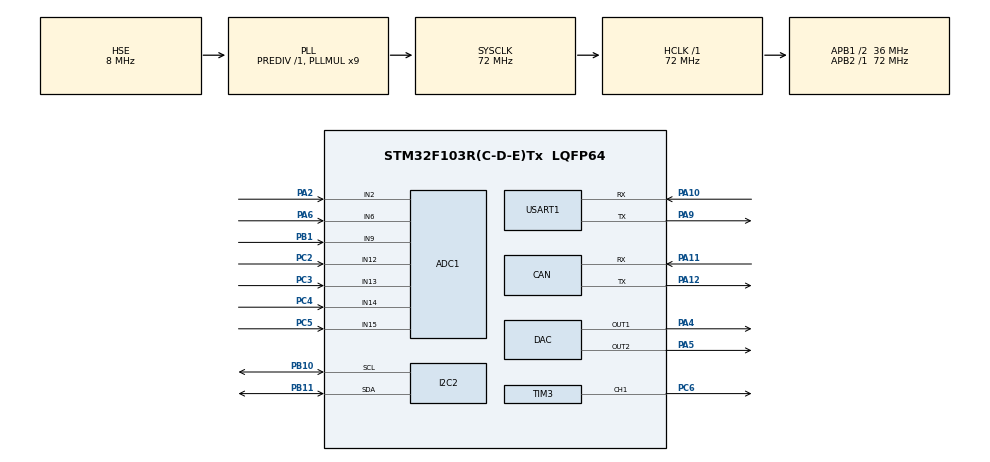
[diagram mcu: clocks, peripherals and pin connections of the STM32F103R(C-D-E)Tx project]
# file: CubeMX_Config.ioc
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ADC1.Channel-0\#ChannelRegularConversion=ADC_CHANNEL_12
ADC1.Channel-1\#ChannelRegularConversion=ADC_CHANNEL_13
ADC1.Channel-2\#ChannelRegularConversion=ADC_CHANNEL_2
ADC1.Channel-3\#ChannelRegularConversion=ADC_CHANNEL_14
ADC1.Channel-4\#ChannelRegularConversion=ADC_CHANNEL_6
ADC1.Channel-5\#ChannelRegularConversion=ADC_CHANNEL_9
ADC1.Channel-6\#ChannelRegularConversion=ADC_CHANNEL_15
ADC1.Channel-7\#ChannelRegularConversion=ADC_CHANNEL_VREFINT
ADC1.ContinuousConvMode=DISABLE
ADC1.ExternalTrigConv=ADC_EXTERNALTRIGCONV_T8_TRGO
ADC1.NbrOfConversion=8
ADC1.NbrOfConversionFlag=1
ADC1.Rank-0\#ChannelRegularConversion=1
ADC1.Rank-1\#ChannelRegularConversion=2
ADC1.Rank-2\#ChannelRegularConversion=3
ADC1.Rank-3\#ChannelRegularConversion=4
ADC1.Rank-4\#ChannelRegularConversion=5
ADC1.Rank-5\#ChannelRegularConversion=6
ADC1.Rank-6\#ChannelRegularConversion=7
ADC1.Rank-7\#ChannelRegularConversion=8
ADC1.SamplingTime-0\#ChannelRegularConversion=ADC_SAMPLETIME_1CYCLE_5
ADC1.SamplingTime-1\#ChannelRegularConversion=ADC_SAMPLETIME_1CYCLE_5
ADC1.SamplingTime-2\#ChannelRegularConversion=ADC_SAMPLETIME_1CYCLE_5
ADC1.SamplingTime-3\#ChannelRegularConversion=ADC_SAMPLETIME_1CYCLE_5
ADC1.SamplingTime-4\#ChannelRegularConversion=ADC_SAMPLETIME_1CYCLE_5
ADC1.SamplingTime-5\#ChannelRegularConversion=ADC_SAMPLETIME_1CYCLE_5
ADC1.SamplingTime-6\#ChannelRegularConversion=ADC_SAMPLETIME_1CYCLE_5
ADC1.SamplingTime-7\#ChannelRegularConversion=ADC_SAMPLETIME_1CYCLE_5
ADC1.master=1
CAN.CalculateTimeBit=1333.33
CAN.CalculateTimeQuantum=444.44444444444446
Dma.ADC1.0.Direction=DMA_PERIPH_TO_MEMORY
Dma.ADC1.0.Instance=DMA1_Channel1
Dma.ADC1.0.MemDataAlignment=DMA_MDATAALIGN_HALFWORD
Dma.ADC1.0.MemInc=DMA_MINC_ENABLE
Dma.ADC1.0.Mode=DMA_CIRCULAR
Dma.ADC1.0.PeriphDataAlignment=DMA_PDATAALIGN_HALFWORD
Dma.ADC1.0.PeriphInc=DMA_PINC_DISABLE
Dma.ADC1.0.Priority=DMA_PRIORITY_HIGH
Dma.Request0=ADC1
I2C2.DutyCycle=I2C_DUTYCYCLE_16_9
I2C2.I2C_Mode=I2C_Fast
Mcu.Family=STM32F1
Mcu.Name=STM32F103R(C-D-E)Tx
Mcu.Package=LQFP64
NVIC.DMA1_Channel1_IRQn=true\:0\:0\:false\:false\:true\:false\:true
NVIC.PriorityGroup=NVIC_PRIORITYGROUP_4
PA10.Mode=Asynchronous
PA10.Signal=USART1_RX
PA11.Mode=Master
PA11.Signal=CAN_RX
PA12.Mode=Master
PA12.Signal=CAN_TX
PA13.Mode=Serial_Wire
PA13.Signal=SYS_JTMS-SWDIO
PA14.Mode=Serial_Wire
PA14.Signal=SYS_JTCK-SWCLK
PA2.Signal=ADCx_IN2
PA4.Signal=COMP_DAC1_group
PA5.Signal=COMP_DAC2_group
PA6.Signal=ADCx_IN6
PA9.Mode=Asynchronous
PA9.Signal=USART1_TX
PB1.Signal=ADCx_IN9
PB10.Mode=I2C
PB10.Signal=I2C2_SCL
PB11.Mode=I2C
PB11.Signal=I2C2_SDA
PC2.Signal=ADCx_IN12
PC3.Signal=ADCx_IN13
PC4.Signal=ADCx_IN14
PC5.Signal=ADCx_IN15
PC6.Signal=S_TIM3_CH1
PD0-OSC_IN.Mode=HSE-External-Oscillator
PD0-OSC_IN.Signal=RCC_OSC_IN
PD1-OSC_OUT.Mode=HSE-External-Oscillator
PD1-OSC_OUT.Signal=RCC_OSC_OUT
ProjectManager.HeapSize=0x200
ProjectManager.StackSize=0x400
ProjectManager.TargetToolchain=MDK-ARM V5
RCC.ADCPresc=RCC_ADCPCLK2_DIV6
RCC.AHBFreq_Value=72000000
RCC.APB1CLKDivider=RCC_HCLK_DIV2
RCC.APB1Freq_Value=36000000
RCC.APB1TimFreq_Value=72000000
RCC.APB2Freq_Value=72000000
RCC.APB2TimFreq_Value=72000000
RCC.HCLKFreq_Value=72000000
RCC.PLLMUL=RCC_PLL_MUL9
RCC.PLLSourceVirtual=RCC_PLLSOURCE_HSE
RCC.SYSCLKFreq_VALUE=72000000
RCC.SYSCLKSource=RCC_SYSCLKSOURCE_PLLCLK
RCC.USBFreq_Value=72000000
SH.ADCx_IN12.0=ADC1_IN12,IN12
SH.ADCx_IN13.0=ADC1_IN13,IN13
SH.ADCx_IN14.0=ADC1_IN14,IN14
SH.ADCx_IN15.0=ADC1_IN15,IN15
SH.ADCx_IN2.0=ADC1_IN2,IN2
SH.ADCx_IN6.0=ADC1_IN6,IN6
SH.ADCx_IN9.0=ADC1_IN9,IN9
SH.COMP_DAC1_group.0=DAC_OUT1,DAC_OUT1
SH.COMP_DAC2_group.0=DAC_OUT2,DAC_OUT2
SH.S_TIM3_CH1.0=TIM3_CH1,PWM Generation1 CH1
TIM3.Channel-PWM\ Generation1\ CH1=TIM_CHANNEL_1
TIM8.AutoReloadPreload=TIM_AUTORELOAD_PRELOAD_ENABLE
TIM8.Period=199
TIM8.Prescaler=71
TIM8.TIM_MasterOutputTrigger=TIM_TRGO_UPDATE
TIM8.TIM_MasterSlaveMode=TIM_MASTERSLAVEMODE_ENABLE
USART1.VirtualMode=VM_ASYNC
VP_ADC1_Vref_Input.Mode=IN-Vrefint
VP_IWDG_VS_IWDG.Mode=IWDG_Activate
VP_TIM2_VS_ClockSourceINT.Mode=Internal
VP_TIM3_VS_ClockSourceINT.Mode=Internal
VP_TIM8_VS_ClockSourceINT.Mode=Internal
board=custom

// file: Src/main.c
/* USER CODE BEGIN Header */
/**
  ******************************************************************************
  * @file           : main.c
  * @brief          : Main program body
  ******************************************************************************
  * @attention
  *
  * <h2><center>&copy; Copyright (c) 2020 STMicroelectronics.
  * All rights reserved.</center></h2>
  *
  * This software component is licensed by ST under BSD 3-Clause license,
  * the "License"; You may not use this file except in compliance with the
  * License. You may obtain a copy of the License at:
  *                        opensource.org/licenses/BSD-3-Clause
  *
  ******************************************************************************
  */
/* USER CODE END Header */

#include "main.h"

ADC_HandleTypeDef hadc1;
DMA_HandleTypeDef hdma_adc1;

CAN_HandleTypeDef hcan;

DAC_HandleTypeDef hdac;

I2C_HandleTypeDef hi2c2;

IWDG_HandleTypeDef hiwdg;

TIM_HandleTypeDef htim2;
TIM_HandleTypeDef htim3;
TIM_HandleTypeDef htim8;

UART_HandleTypeDef huart1;

/* USER CODE BEGIN PV */
uint16_t adc_data_Buff[1][8]; // 用于存放adc采样数据的数组
/* USER CODE END PV */

void SystemClock_Config(void);
static void MX_GPIO_Init(void);
static void MX_ADC1_Init(void);
static void MX_CAN_Init(void);
static void MX_DAC_Init(void);
static void MX_TIM3_Init(void);
static void MX_USART1_UART_Init(void);
static void MX_I2C2_Init(void);
static void MX_DMA_Init(void);
static void MX_IWDG_Init(void);
static void MX_TIM8_Init(void);
static void MX_TIM2_Init(void);

int main(void)
{

  /* MCU Configuration--------------------------------------------------------*/

  /* Reset of all peripherals, Initializes the Flash interface and the Systick. */
  HAL_Init();

  /* Configure the system clock */
  SystemClock_Config();

  /* Initialize all configured peripherals */
  MX_GPIO_Init();
	MX_DMA_Init();
  MX_ADC1_Init();
  MX_CAN_Init();
  MX_DAC_Init();
  MX_TIM3_Init();
  MX_USART1_UART_Init();
  MX_I2C2_Init();
  MX_IWDG_Init();
  MX_TIM8_Init();
  MX_TIM2_Init();
  /* USER CODE BEGIN 2 */
	HAL_ADC_Start_DMA(&hadc1, (uint32_t *)adc_data_Buff, 8); //启动DMA
	HAL_TIM_Base_Start_IT(&htim8);												//启动定时器，触发ADC-DMA采样
	HAL_Delay(100);
  /* USER CODE END 2 */

  /* Infinite loop */
  while (1)
  {

  }
}

void SystemClock_Config(void)
{
  RCC_OscInitTypeDef RCC_OscInitStruct = {0};
  RCC_ClkInitTypeDef RCC_ClkInitStruct = {0};
  RCC_PeriphCLKInitTypeDef PeriphClkInit = {0};

  /** Initializes the CPU, AHB and APB busses clocks
  */
  RCC_OscInitStruct.OscillatorType = RCC_OSCILLATORTYPE_LSI|RCC_OSCILLATORTYPE_HSE;
  RCC_OscInitStruct.HSEState = RCC_HSE_ON;
  RCC_OscInitStruct.HSEPredivValue = RCC_HSE_PREDIV_DIV1;
  RCC_OscInitStruct.HSIState = RCC_HSI_ON;
  RCC_OscInitStruct.LSIState = RCC_LSI_ON;
  RCC_OscInitStruct.PLL.PLLState = RCC_PLL_ON;
  RCC_OscInitStruct.PLL.PLLSource = RCC_PLLSOURCE_HSE;
  RCC_OscInitStruct.PLL.PLLMUL = RCC_PLL_MUL9;
  if (HAL_RCC_OscConfig(&RCC_OscInitStruct) != HAL_OK)
  {
    Error_Handler();
  }
  /** Initializes the CPU, AHB and APB busses clocks
  */
  RCC_ClkInitStruct.ClockType = RCC_CLOCKTYPE_HCLK|RCC_CLOCKTYPE_SYSCLK
                              |RCC_CLOCKTYPE_PCLK1|RCC_CLOCKTYPE_PCLK2;
  RCC_ClkInitStruct.SYSCLKSource = RCC_SYSCLKSOURCE_PLLCLK;
  RCC_ClkInitStruct.AHBCLKDivider = RCC_SYSCLK_DIV1;
  RCC_ClkInitStruct.APB1CLKDivider = RCC_HCLK_DIV2;
  RCC_ClkInitStruct.APB2CLKDivider = RCC_HCLK_DIV1;

  if (HAL_RCC_ClockConfig(&RCC_ClkInitStruct, FLASH_LATENCY_2) != HAL_OK)
  {
    Error_Handler();
  }
  PeriphClkInit.PeriphClockSelection = RCC_PERIPHCLK_ADC;
  PeriphClkInit.AdcClockSelection = RCC_ADCPCLK2_DIV6;
  if (HAL_RCCEx_PeriphCLKConfig(&PeriphClkInit) != HAL_OK)
  {
    Error_Handler();
  }
}

static void MX_ADC1_Init(void)
{

  ADC_ChannelConfTypeDef sConfig = {0};

  /** Common config
  */
  hadc1.Instance = ADC1;
  hadc1.Init.ScanConvMode = ADC_SCAN_ENABLE;
  hadc1.Init.ContinuousConvMode = DISABLE;
  hadc1.Init.DiscontinuousConvMode = DISABLE;
  hadc1.Init.ExternalTrigConv = ADC_EXTERNALTRIGCONV_T8_TRGO;
  hadc1.Init.DataAlign = ADC_DATAALIGN_RIGHT;
  hadc1.Init.NbrOfConversion = 8;
  if (HAL_ADC_Init(&hadc1) != HAL_OK)
  {
    Error_Handler();
  }
  /** Enable or disable the remapping of ADC1_ETRGREG:
  * ADC1 External Event regular conversion is connected to TIM8 TRG0
  */
  __HAL_AFIO_REMAP_ADC1_ETRGREG_ENABLE();
  /** Configure Regular Channel
  */
  sConfig.Channel = ADC_CHANNEL_12;
  sConfig.Rank = ADC_REGULAR_RANK_1;
  sConfig.SamplingTime = ADC_SAMPLETIME_1CYCLE_5;
  if (HAL_ADC_ConfigChannel(&hadc1, &sConfig) != HAL_OK)
  {
    Error_Handler();
  }
  /** Configure Regular Channel
  */
  sConfig.Channel = ADC_CHANNEL_13;
  sConfig.Rank = ADC_REGULAR_RANK_2;
  if (HAL_ADC_ConfigChannel(&hadc1, &sConfig) != HAL_OK)
  {
    Error_Handler();
  }
  /** Configure Regular Channel
  */
  sConfig.Channel = ADC_CHANNEL_2;
  sConfig.Rank = ADC_REGULAR_RANK_3;
  if (HAL_ADC_ConfigChannel(&hadc1, &sConfig) != HAL_OK)
  {
    Error_Handler();
  }
  /** Configure Regular Channel
  */
  sConfig.Channel = ADC_CHANNEL_14;
  sConfig.Rank = ADC_REGULAR_RANK_4;
  if (HAL_ADC_ConfigChannel(&hadc1, &sConfig) != HAL_OK)
  {
    Error_Handler();
  }
  /** Configure Regular Channel
  */
  sConfig.Channel = ADC_CHANNEL_6;
  sConfig.Rank = ADC_REGULAR_RANK_5;
  if (HAL_ADC_ConfigChannel(&hadc1, &sConfig) != HAL_OK)
  {
    Error_Handler();
  }
  /** Configure Regular Channel
  */
  sConfig.Channel = ADC_CHANNEL_9;
  sConfig.Rank = ADC_REGULAR_RANK_6;
  if (HAL_ADC_ConfigChannel(&hadc1, &sConfig) != HAL_OK)
  {
    Error_Handler();
  }
  /** Configure Regular Channel
  */
  sConfig.Channel = ADC_CHANNEL_15;
  sConfig.Rank = ADC_REGULAR_RANK_7;
  if (HAL_ADC_ConfigChannel(&hadc1, &sConfig) != HAL_OK)
  {
    Error_Handler();
  }
  /** Configure Regular Channel
  */
  sConfig.Channel = ADC_CHANNEL_VREFINT;
  sConfig.Rank = ADC_REGULAR_RANK_8;
  if (HAL_ADC_ConfigChannel(&hadc1, &sConfig) != HAL_OK)
  {
    Error_Handler();
  }

}

static void MX_CAN_Init(void)
{

  hcan.Instance = CAN1;
  hcan.Init.Prescaler = 16;
  hcan.Init.Mode = CAN_MODE_NORMAL;
  hcan.Init.SyncJumpWidth = CAN_SJW_1TQ;
  hcan.Init.TimeSeg1 = CAN_BS1_1TQ;
  hcan.Init.TimeSeg2 = CAN_BS2_1TQ;
  hcan.Init.TimeTriggeredMode = DISABLE;
  hcan.Init.AutoBusOff = DISABLE;
  hcan.Init.AutoWakeUp = DISABLE;
  hcan.Init.AutoRetransmission = DISABLE;
  hcan.Init.ReceiveFifoLocked = DISABLE;
  hcan.Init.TransmitFifoPriority = DISABLE;
  if (HAL_CAN_Init(&hcan) != HAL_OK)
  {
    Error_Handler();
  }

}

static void MX_DAC_Init(void)
{

  DAC_ChannelConfTypeDef sConfig = {0};

  /** DAC Initialization
  */
  hdac.Instance = DAC;
  if (HAL_DAC_Init(&hdac) != HAL_OK)
  {
    Error_Handler();
  }
  /** DAC channel OUT1 config
  */
  sConfig.DAC_Trigger = DAC_TRIGGER_NONE;
  sConfig.DAC_OutputBuffer = DAC_OUTPUTBUFFER_ENABLE;
  if (HAL_DAC_ConfigChannel(&hdac, &sConfig, DAC_CHANNEL_1) != HAL_OK)
  {
    Error_Handler();
  }
  /** DAC channel OUT2 config
  */
  if (HAL_DAC_ConfigChannel(&hdac, &sConfig, DAC_CHANNEL_2) != HAL_OK)
  {
    Error_Handler();
  }

}

static void MX_I2C2_Init(void)
{

  hi2c2.Instance = I2C2;
  hi2c2.Init.ClockSpeed = 400000;
  hi2c2.Init.DutyCycle = I2C_DUTYCYCLE_16_9;
  hi2c2.Init.OwnAddress1 = 0;
  hi2c2.Init.AddressingMode = I2C_ADDRESSINGMODE_7BIT;
  hi2c2.Init.DualAddressMode = I2C_DUALADDRESS_DISABLE;
  hi2c2.Init.OwnAddress2 = 0;
  hi2c2.Init.GeneralCallMode = I2C_GENERALCALL_DISABLE;
  hi2c2.Init.NoStretchMode = I2C_NOSTRETCH_DISABLE;
  if (HAL_I2C_Init(&hi2c2) != HAL_OK)
  {
    Error_Handler();
  }

}

static void MX_IWDG_Init(void)
{

  hiwdg.Instance = IWDG;
  hiwdg.Init.Prescaler = IWDG_PRESCALER_4;
  hiwdg.Init.Reload = 4095;
  if (HAL_IWDG_Init(&hiwdg) != HAL_OK)
  {
    Error_Handler();
  }

}

static void MX_TIM2_Init(void)
{

  TIM_ClockConfigTypeDef sClockSourceConfig = {0};
  TIM_MasterConfigTypeDef sMasterConfig = {0};

  htim2.Instance = TIM2;
  htim2.Init.Prescaler = 0;
  htim2.Init.CounterMode = TIM_COUNTERMODE_UP;
  htim2.Init.Period = 0;
  htim2.Init.ClockDivision = TIM_CLOCKDIVISION_DIV1;
  htim2.Init.AutoReloadPreload = TIM_AUTORELOAD_PRELOAD_DISABLE;
  if (HAL_TIM_Base_Init(&htim2) != HAL_OK)
  {
    Error_Handler();
  }
  sClockSourceConfig.ClockSource = TIM_CLOCKSOURCE_INTERNAL;
  if (HAL_TIM_ConfigClockSource(&htim2, &sClockSourceConfig) != HAL_OK)
  {
    Error_Handler();
  }
  sMasterConfig.MasterOutputTrigger = TIM_TRGO_RESET;
  sMasterConfig.MasterSlaveMode = TIM_MASTERSLAVEMODE_DISABLE;
  if (HAL_TIMEx_MasterConfigSynchronization(&htim2, &sMasterConfig) != HAL_OK)
  {
    Error_Handler();
  }

}

static void MX_TIM3_Init(void)
{

  TIM_ClockConfigTypeDef sClockSourceConfig = {0};
  TIM_MasterConfigTypeDef sMasterConfig = {0};
  TIM_OC_InitTypeDef sConfigOC = {0};

  htim3.Instance = TIM3;
  htim3.Init.Prescaler = 0;
  htim3.Init.CounterMode = TIM_COUNTERMODE_UP;
  htim3.Init.Period = 0;
  htim3.Init.ClockDivision = TIM_CLOCKDIVISION_DIV1;
  htim3.Init.AutoReloadPreload = TIM_AUTORELOAD_PRELOAD_DISABLE;
  if (HAL_TIM_Base_Init(&htim3) != HAL_OK)
  {
    Error_Handler();
  }
  sClockSourceConfig.ClockSource = TIM_CLOCKSOURCE_INTERNAL;
  if (HAL_TIM_ConfigClockSource(&htim3, &sClockSourceConfig) != HAL_OK)
  {
    Error_Handler();
  }
  if (HAL_TIM_PWM_Init(&htim3) != HAL_OK)
  {
    Error_Handler();
  }
  sMasterConfig.MasterOutputTrigger = TIM_TRGO_RESET;
  sMasterConfig.MasterSlaveMode = TIM_MASTERSLAVEMODE_DISABLE;
  if (HAL_TIMEx_MasterConfigSynchronization(&htim3, &sMasterConfig) != HAL_OK)
  {
    Error_Handler();
  }
  sConfigOC.OCMode = TIM_OCMODE_PWM1;
  sConfigOC.Pulse = 0;
  sConfigOC.OCPolarity = TIM_OCPOLARITY_HIGH;
  sConfigOC.OCFastMode = TIM_OCFAST_DISABLE;
  if (HAL_TIM_PWM_ConfigChannel(&htim3, &sConfigOC, TIM_CHANNEL_1) != HAL_OK)
  {
    Error_Handler();
  }
  HAL_TIM_MspPostInit(&htim3);

}

static void MX_TIM8_Init(void)
{

  TIM_ClockConfigTypeDef sClockSourceConfig = {0};
  TIM_MasterConfigTypeDef sMasterConfig = {0};

  htim8.Instance = TIM8;
  htim8.Init.Prescaler = 71;
  htim8.Init.CounterMode = TIM_COUNTERMODE_UP;
  htim8.Init.Period = 199;
  htim8.Init.ClockDivision = TIM_CLOCKDIVISION_DIV1;
  htim8.Init.RepetitionCounter = 0;
  htim8.Init.AutoReloadPreload = TIM_AUTORELOAD_PRELOAD_ENABLE;
  if (HAL_TIM_Base_Init(&htim8) != HAL_OK)
  {
    Error_Handler();
  }
  sClockSourceConfig.ClockSource = TIM_CLOCKSOURCE_INTERNAL;
  if (HAL_TIM_ConfigClockSource(&htim8, &sClockSourceConfig) != HAL_OK)
  {
    Error_Handler();
  }
  sMasterConfig.MasterOutputTrigger = TIM_TRGO_UPDATE;
  sMasterConfig.MasterSlaveMode = TIM_MASTERSLAVEMODE_ENABLE;
  if (HAL_TIMEx_MasterConfigSynchronization(&htim8, &sMasterConfig) != HAL_OK)
  {
    Error_Handler();
  }

}

static void MX_USART1_UART_Init(void)
{

  huart1.Instance = USART1;
  huart1.Init.BaudRate = 115200;
  huart1.Init.WordLength = UART_WORDLENGTH_8B;
  huart1.Init.StopBits = UART_STOPBITS_1;
  huart1.Init.Parity = UART_PARITY_NONE;
  huart1.Init.Mode = UART_MODE_TX_RX;
  huart1.Init.HwFlowCtl = UART_HWCONTROL_NONE;
  huart1.Init.OverSampling = UART_OVERSAMPLING_16;
  if (HAL_UART_Init(&huart1) != HAL_OK)
  {
    Error_Handler();
  }

}

static void MX_DMA_Init(void)
{

  /* DMA controller clock enable */
  __HAL_RCC_DMA1_CLK_ENABLE();

  /* DMA interrupt init */
  /* DMA1_Channel1_IRQn interrupt configuration */
  HAL_NVIC_SetPriority(DMA1_Channel1_IRQn, 0, 0);
  HAL_NVIC_EnableIRQ(DMA1_Channel1_IRQn);

}

static void MX_GPIO_Init(void)
{

  /* GPIO Ports Clock Enable */
  __HAL_RCC_GPIOD_CLK_ENABLE();
  __HAL_RCC_GPIOC_CLK_ENABLE();
  __HAL_RCC_GPIOA_CLK_ENABLE();
  __HAL_RCC_GPIOB_CLK_ENABLE();

}

void Error_Handler(void)
{
}

/************************ (C) COPYRIGHT STMicroelectronics *****END OF FILE****/
